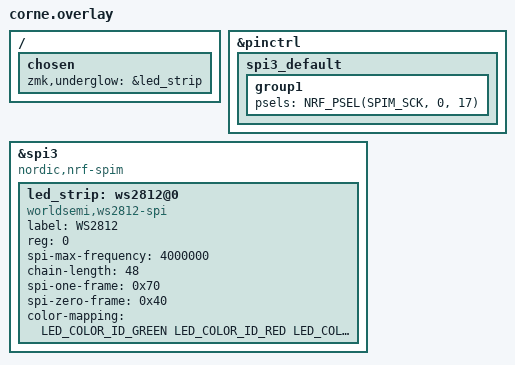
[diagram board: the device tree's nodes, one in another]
&pinctrl {
    spi3_default: spi3_default {
        group1 {
            psels = <NRF_PSEL(SPIM_SCK, 0, 17)>;
        };
    };
};

&spi3 {
    compatible = "nordic,nrf-spim";
    status = "okay";

    led_strip: ws2812@0 {
        compatible = "worldsemi,ws2812-spi";
        label = "WS2812";

        /* SPI */
        reg = <0>; /* ignored, but necessary for SPI bindings */
        spi-max-frequency = <4000000>;

        /* WS2812 */
        chain-length = <48>; /* number of LEDs */
        spi-one-frame = <0x70>;
        spi-zero-frame = <0x40>;
        color-mapping = <LED_COLOR_ID_GREEN LED_COLOR_ID_RED LED_COLOR_ID_BLUE>;
    };
};

/ {
    chosen {
        zmk,underglow = &led_strip;
    };
};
